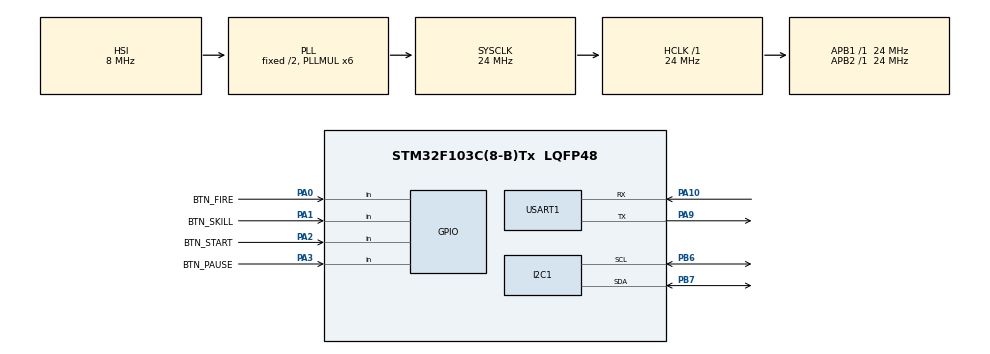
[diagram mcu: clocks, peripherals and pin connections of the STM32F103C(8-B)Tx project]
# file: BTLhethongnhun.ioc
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FREERTOS.INCLUDE_vTaskDelayUntil=1
FREERTOS.Tasks01=defaultTask,0,128,StartDefaultTask,Default,NULL,Dynamic,NULL,NULL
FREERTOS.configTOTAL_HEAP_SIZE=8192
I2C1.I2C_Mode=I2C_Fast
Mcu.Family=STM32F1
Mcu.Name=STM32F103C(8-B)Tx
Mcu.Package=LQFP48
NVIC.PriorityGroup=NVIC_PRIORITYGROUP_4
NVIC.TIM4_IRQn=true\:15\:0\:false\:false\:true\:false\:false\:true\:true
NVIC.TimeBase=TIM4_IRQn
NVIC.TimeBaseIP=TIM4
PA0-WKUP.GPIO_Label=BTN_FIRE
PA0-WKUP.GPIO_PuPd=GPIO_PULLUP
PA0-WKUP.Signal=GPIO_Input
PA1.GPIO_Label=BTN_SKILL
PA1.GPIO_PuPd=GPIO_PULLUP
PA1.Signal=GPIO_Input
PA10.Mode=Asynchronous
PA10.Signal=USART1_RX
PA13.Mode=Serial_Wire
PA13.Signal=SYS_JTMS-SWDIO
PA14.Mode=Serial_Wire
PA14.Signal=SYS_JTCK-SWCLK
PA2.GPIO_Label=BTN_START
PA2.GPIO_PuPd=GPIO_PULLUP
PA2.Signal=GPIO_Input
PA3.GPIO_Label=BTN_PAUSE
PA3.GPIO_PuPd=GPIO_PULLUP
PA3.Signal=GPIO_Input
PA9.Mode=Asynchronous
PA9.Signal=USART1_TX
PB6.Mode=I2C
PB6.Signal=I2C1_SCL
PB7.Mode=I2C
PB7.Signal=I2C1_SDA
PD0-OSC_IN.Mode=HSE-External-Oscillator
PD0-OSC_IN.Signal=RCC_OSC_IN
PD1-OSC_OUT.Mode=HSE-External-Oscillator
PD1-OSC_OUT.Signal=RCC_OSC_OUT
ProjectManager.HeapSize=0x200
ProjectManager.StackSize=0x400
ProjectManager.TargetToolchain=STM32CubeIDE
RCC.AHBFreq_Value=24000000
RCC.APB1Freq_Value=24000000
RCC.APB1TimFreq_Value=24000000
RCC.APB2Freq_Value=24000000
RCC.APB2TimFreq_Value=24000000
RCC.HCLKFreq_Value=24000000
RCC.PLLMUL=RCC_PLL_MUL6
RCC.SYSCLKFreq_VALUE=24000000
RCC.SYSCLKSource=RCC_SYSCLKSOURCE_PLLCLK
RCC.USBFreq_Value=24000000
USART1.VirtualMode=VM_ASYNC
VP_FREERTOS_VS_CMSIS_V1.Mode=CMSIS_V1
VP_SYS_VS_tim4.Mode=TIM4
board=custom

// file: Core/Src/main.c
/* USER CODE BEGIN Header */
/**
  ******************************************************************************
  * @file           : main.c
  * @brief          : Main program body
  ******************************************************************************
  * @attention
  *
  * Copyright (c) 2026 STMicroelectronics.
  * All rights reserved.
  *
  * This software is licensed under terms that can be found in the LICENSE file
  * in the root directory of this software component.
  * If no LICENSE file comes with this software, it is provided AS-IS.
  *
  ******************************************************************************
  */
/* USER CODE END Header */
#include "main.h"
#include "cmsis_os.h"
#include "i2c.h"
#include "usart.h"
#include "gpio.h"

void SystemClock_Config(void);
void MX_FREERTOS_Init(void);

int main(void)
{

  /* MCU Configuration--------------------------------------------------------*/

  /* Reset of all peripherals, Initializes the Flash interface and the Systick. */
  HAL_Init();

  /* Configure the system clock */
  SystemClock_Config();

  /* Initialize all configured peripherals */
  MX_GPIO_Init();
  MX_I2C1_Init();
  MX_USART1_UART_Init();

  /* Call init function for freertos objects (in cmsis_os2.c) */
  MX_FREERTOS_Init();

  /* Start scheduler */
  osKernelStart();

  /* We should never get here as control is now taken by the scheduler */

  /* Infinite loop */
  while (1)
  {

  }
}

void SystemClock_Config(void)
{
  RCC_OscInitTypeDef RCC_OscInitStruct = {0};
  RCC_ClkInitTypeDef RCC_ClkInitStruct = {0};

  /** Initializes the RCC Oscillators according to the specified parameters
  * in the RCC_OscInitTypeDef structure.
  */
  RCC_OscInitStruct.OscillatorType = RCC_OSCILLATORTYPE_HSI;
  RCC_OscInitStruct.HSIState = RCC_HSI_ON;
  RCC_OscInitStruct.HSICalibrationValue = RCC_HSICALIBRATION_DEFAULT;
  RCC_OscInitStruct.PLL.PLLState = RCC_PLL_ON;
  RCC_OscInitStruct.PLL.PLLSource = RCC_PLLSOURCE_HSI_DIV2;
  RCC_OscInitStruct.PLL.PLLMUL = RCC_PLL_MUL6;
  if (HAL_RCC_OscConfig(&RCC_OscInitStruct) != HAL_OK)
  {
    Error_Handler();
  }

  /** Initializes the CPU, AHB and APB buses clocks
  */
  RCC_ClkInitStruct.ClockType = RCC_CLOCKTYPE_HCLK|RCC_CLOCKTYPE_SYSCLK
                              |RCC_CLOCKTYPE_PCLK1|RCC_CLOCKTYPE_PCLK2;
  RCC_ClkInitStruct.SYSCLKSource = RCC_SYSCLKSOURCE_PLLCLK;
  RCC_ClkInitStruct.AHBCLKDivider = RCC_SYSCLK_DIV1;
  RCC_ClkInitStruct.APB1CLKDivider = RCC_HCLK_DIV1;
  RCC_ClkInitStruct.APB2CLKDivider = RCC_HCLK_DIV1;

  if (HAL_RCC_ClockConfig(&RCC_ClkInitStruct, FLASH_LATENCY_0) != HAL_OK)
  {
    Error_Handler();
  }
}

void HAL_TIM_PeriodElapsedCallback(TIM_HandleTypeDef *htim)
{
  if (htim->Instance == TIM4)
  {
    HAL_IncTick();
  }
}

void Error_Handler(void)
{
  __disable_irq();
  while (1)
  {
  }
}

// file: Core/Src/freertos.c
/* USER CODE BEGIN Header */
/**
  ******************************************************************************
  * File Name          : freertos.c
  * Description        : Code for freertos applications
  ******************************************************************************
  * @attention
  *
  * Copyright (c) 2026 STMicroelectronics.
  * All rights reserved.
  *
  * This software is licensed under terms that can be found in the LICENSE file
  * in the root directory of this software component.
  * If no LICENSE file comes with this software, it is provided AS-IS.
  *
  ******************************************************************************
  */
/* USER CODE END Header */

#include "FreeRTOS.h"
#include "task.h"
#include "main.h"
#include "cmsis_os.h"

/* USER CODE BEGIN Includes */
#include "app_rtos.h"
/* USER CODE END Includes */

osThreadId defaultTaskHandle;

void StartDefaultTask(void const * argument);

void MX_FREERTOS_Init(void); /* (MISRA C 2004 rule 8.1) */

/* GetIdleTaskMemory prototype (linked to static allocation support) */
void vApplicationGetIdleTaskMemory( StaticTask_t **ppxIdleTaskTCBBuffer, StackType_t **ppxIdleTaskStackBuffer, uint32_t *pulIdleTaskStackSize );

/* USER CODE BEGIN GET_IDLE_TASK_MEMORY */
static StaticTask_t xIdleTaskTCBBuffer;
static StackType_t xIdleStack[configMINIMAL_STACK_SIZE];

void vApplicationGetIdleTaskMemory( StaticTask_t **ppxIdleTaskTCBBuffer, StackType_t **ppxIdleTaskStackBuffer, uint32_t *pulIdleTaskStackSize )
{
  *ppxIdleTaskTCBBuffer = &xIdleTaskTCBBuffer;
  *ppxIdleTaskStackBuffer = &xIdleStack[0];
  *pulIdleTaskStackSize = configMINIMAL_STACK_SIZE;
  /* place for user code */
}
/* USER CODE END GET_IDLE_TASK_MEMORY */

void MX_FREERTOS_Init(void) {

  /* Create the thread(s) */
  /* definition and creation of defaultTask */
  osThreadDef(defaultTask, StartDefaultTask, osPriorityNormal, 0, 128);
  defaultTaskHandle = osThreadCreate(osThread(defaultTask), NULL);

  /* USER CODE BEGIN RTOS_THREADS */
  App_Init();   /* tạo task Input / Game / Render + mutex của SpaceShooter */
  /* USER CODE END RTOS_THREADS */

}

void StartDefaultTask(void const * argument)
{
  /* USER CODE BEGIN StartDefaultTask */
  /* Infinite loop */
  for(;;)
  {
    osDelay(1000);   /* task này không làm gì, ngủ lâu để nhường CPU cho game */
  }
  /* USER CODE END StartDefaultTask */
}
